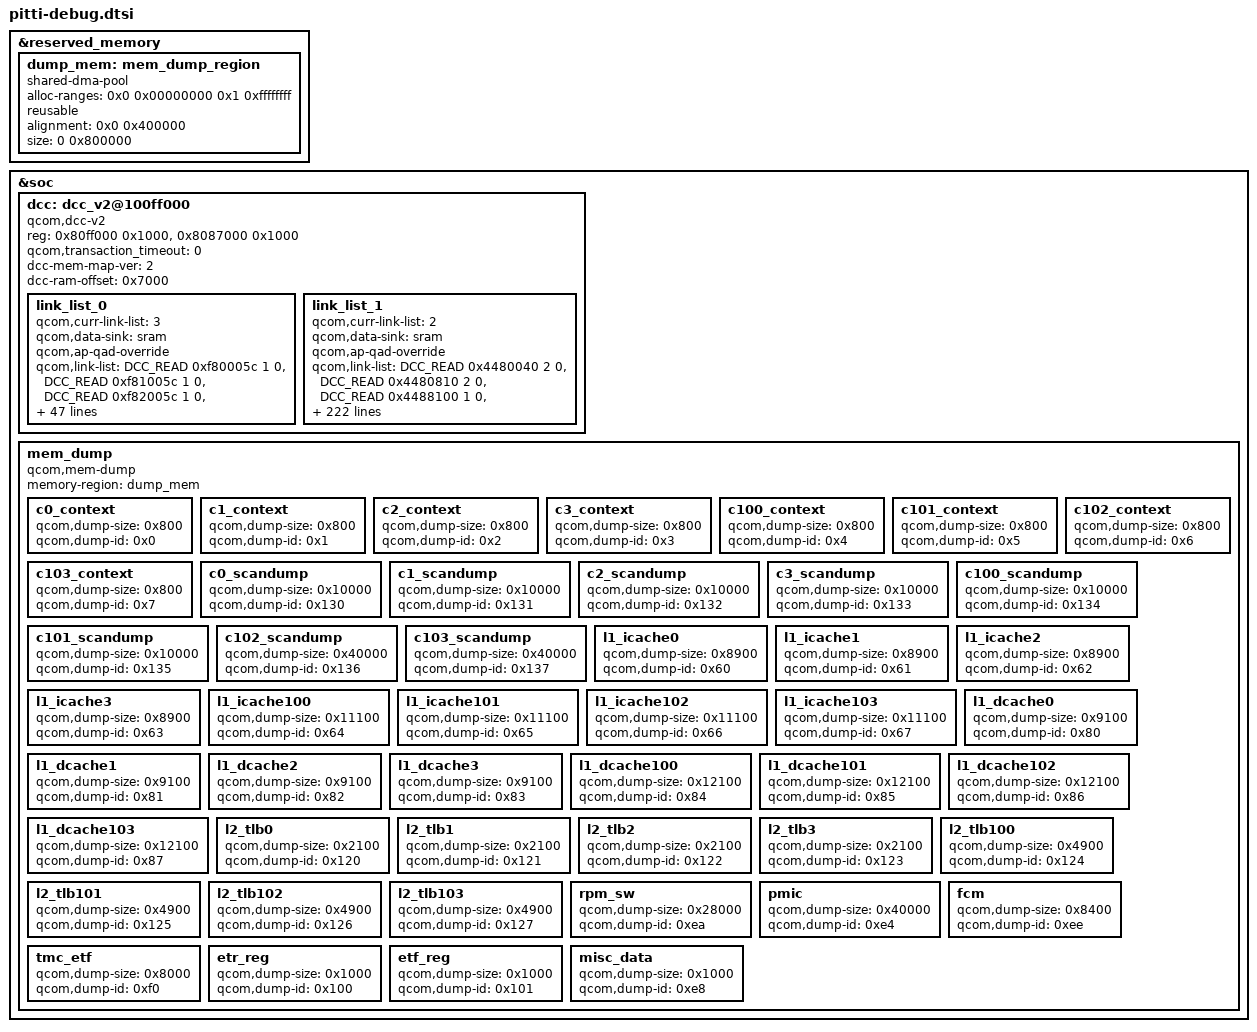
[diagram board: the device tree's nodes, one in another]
#include <dt-bindings/soc/qcom,dcc_v2.h>

&reserved_memory {
	#address-cells = <2>;
	#size-cells = <2>;
	ranges;

	dump_mem: mem_dump_region {
		compatible = "shared-dma-pool";
		alloc-ranges = <0x0 0x00000000 0x1 0xffffffff>;
		reusable;
		alignment = <0x0 0x400000>;
		size = <0 0x800000>;
	};
};

&soc {
	dcc: dcc_v2@100ff000 {
		compatible = "qcom,dcc-v2";
		reg = <0x80ff000 0x1000>,
		      <0x8087000 0x1000>;

		qcom,transaction_timeout = <0>;
		dcc-mem-map-ver = <2>;

		reg-names = "dcc-base", "dcc-ram-base";
		dcc-ram-offset = <0x7000>;

		link_list_0 {
			qcom,curr-link-list = <3>;
			qcom,data-sink = "sram";
			qcom,ap-qad-override;
			qcom,link-list = <DCC_READ 0xf80005c 1 0>,
				<DCC_READ 0xf81005c 1 0>,
				<DCC_READ 0xf82005c 1 0>,
				<DCC_READ 0xf83005c 1 0>,
				<DCC_READ 0xf84005c 1 0>,
				<DCC_READ 0xf85005c 1 0>,
				<DCC_READ 0xf86005c 1 0>,
				<DCC_READ 0xf87005c 1 0>,
				<DCC_READ 0xf40003c 1 0>,
				<DCC_READ 0x1b60100 11 0>,
				<DCC_READ 0x1880240 1 0>,
				<DCC_READ 0x1880248 1 0>,
				<DCC_READ 0x1880300 8 0>,
				<DCC_READ 0x1881100 2 0>,
				<DCC_READ 0x1900240 5 0>,
				<DCC_READ 0x1900258 1 0>,
				<DCC_READ 0x1900000 1 0>,
				<DCC_READ 0x1900010 1 0>,
				<DCC_READ 0x1900020 8 0>,
				<DCC_READ 0x1480140 1 0>,
				<DCC_READ 0x1481140 1 0>,
				<DCC_READ 0xf400038 1 0>,
				<DCC_READ 0xf41000c 1 0>,
				<DCC_READ 0xf400438 1 0>,
				<DCC_READ 0xf800058 1 0>,
				<DCC_READ 0xf810058 1 0>,
				<DCC_READ 0xf820058 1 0>,
				<DCC_READ 0xf830058 1 0>,
				<DCC_READ 0xf840058 1 0>,
				<DCC_READ 0xf850058 1 0>,
				<DCC_READ 0xf860058 1 0>,
				<DCC_READ 0xf870058 1 0>,
				<DCC_READ 0xf800060 1 0>,
				<DCC_READ 0xf810060 1 0>,
				<DCC_READ 0xf820060 1 0>,
				<DCC_READ 0xf830060 1 0>,
				<DCC_READ 0xf840060 1 0>,
				<DCC_READ 0xf850060 1 0>,
				<DCC_READ 0xf860060 1 0>,
				<DCC_READ 0xf870060 1 0>,
				<DCC_READ 0xf880060 1 0>,
				<DCC_READ 0xf600440 1 0>,
				<DCC_READ 0xf60043c 1 0>,
				<DCC_READ 0xf600404 1 0>,
				<DCC_READ 0x4407000 5 0>,
				<DCC_READ 0x4402000 2 0>,
				<DCC_READ 0xf200104 29 0>,
				<DCC_READ 0xf200184 29 0>,
				<DCC_READ 0xf200204 29 0>,
				<DCC_READ 0xf200284 29 0>;
		};

		link_list_1 {
			qcom,curr-link-list = <2>;
			qcom,data-sink = "sram";
			qcom,ap-qad-override;
			qcom,link-list = <DCC_READ 0x4480040 2 0>,
				<DCC_READ 0x4480810 2 0>,
				<DCC_READ 0x4488100 1 0>,
				<DCC_READ 0x4488400 2 0>,
				<DCC_READ 0x4488410 1 0>,
				<DCC_READ 0x4488420 2 0>,
				<DCC_READ 0x4488430 2 0>,
				<DCC_READ 0x4488440 2 0>,
				<DCC_READ 0x4488450 1 0>,
				<DCC_READ 0x448c100 1 0>,
				<DCC_READ 0x448c400 2 0>,
				<DCC_READ 0x448c410 1 0>,
				<DCC_READ 0x448c420 2 0>,
				<DCC_READ 0x448c430 2 0>,
				<DCC_READ 0x448c440 2 0>,
				<DCC_READ 0x448c450 1 0>,
				<DCC_READ 0x4490100 1 0>,
				<DCC_READ 0x4490400 2 0>,
				<DCC_READ 0x4490410 1 0>,
				<DCC_READ 0x4490420 2 0>,
				<DCC_READ 0x4490430 2 0>,
				<DCC_READ 0x4490440 2 0>,
				<DCC_READ 0x4490450 1 0>,
				<DCC_READ 0x4494100 1 0>,
				<DCC_READ 0x4494400 2 0>,
				<DCC_READ 0x4494410 1 0>,
				<DCC_READ 0x4494420 2 0>,
				<DCC_READ 0x4494430 2 0>,
				<DCC_READ 0x4494440 2 0>,
				<DCC_READ 0x4494450 1 0>,
				<DCC_READ 0x4498100 1 0>,
				<DCC_READ 0x4498400 2 0>,
				<DCC_READ 0x4498410 1 0>,
				<DCC_READ 0x4498420 2 0>,
				<DCC_READ 0x4498430 2 0>,
				<DCC_READ 0x4498440 2 0>,
				<DCC_READ 0x4498450 1 0>,
				<DCC_READ 0x449c400 2 0>,
				<DCC_READ 0x449c420 2 0>,
				<DCC_READ 0x449c430 1 0>,
				<DCC_READ 0x449c440 2 0>,
				<DCC_READ 0x449c450 1 0>,
				<DCC_READ 0x44a0400 2 0>,
				<DCC_READ 0x44a0420 2 0>,
				<DCC_READ 0x44a0430 1 0>,
				<DCC_READ 0x44a0440 2 0>,
				<DCC_READ 0x44a0450 1 0>,
				<DCC_READ 0x44a4100 1 0>,
				<DCC_READ 0x44a4400 2 0>,
				<DCC_READ 0x44a4410 1 0>,
				<DCC_READ 0x44a4420 2 0>,
				<DCC_READ 0x44a4430 2 0>,
				<DCC_READ 0x44a4440 2 0>,
				<DCC_READ 0x44a4450 1 0>,
				<DCC_READ 0x44b0020 1 0>,
				<DCC_READ 0x44b0100 1 0>,
				<DCC_READ 0x44b0120 5 0>,
				<DCC_READ 0x44b0140 1 0>,
				<DCC_READ 0x44b0450 1 0>,
				<DCC_READ 0x44b0500 1 0>,
				<DCC_READ 0x44b0520 1 0>,
				<DCC_READ 0x44b0560 1 0>,
				<DCC_READ 0x44b05a0 1 0>,
				<DCC_READ 0x44b0710 1 0>,
				<DCC_READ 0x44b0720 1 0>,
				<DCC_READ 0x44b0a40 1 0>,
				<DCC_READ 0x44b1800 1 0>,
				<DCC_READ 0x44b408c 1 0>,
				<DCC_READ 0x44b409c 3 0>,
				<DCC_READ 0x44b40b8 1 0>,
				<DCC_READ 0x44b5070 2 0>,
				<DCC_READ 0x44bc020 1 0>,
				<DCC_READ 0x44bc100 1 0>,
				<DCC_READ 0x44bc120 4 0>,
				<DCC_READ 0x44bc140 1 0>,
				<DCC_READ 0x44bc450 1 0>,
				<DCC_READ 0x44bc500 1 0>,
				<DCC_READ 0x44bc520 1 0>,
				<DCC_READ 0x44bc560 1 0>,
				<DCC_READ 0x44bc5a0 1 0>,
				<DCC_READ 0x44bc710 1 0>,
				<DCC_READ 0x44bc720 1 0>,
				<DCC_READ 0x44bca40 1 0>,
				<DCC_READ 0x44bd800 1 0>,
				<DCC_READ 0x44c008c 1 0>,
				<DCC_READ 0x44c009c 3 0>,
				<DCC_READ 0x44c00b8 1 0>,
				<DCC_READ 0x44c1070 2 0>,
				<DCC_READ 0x44c8220 1 0>,
				<DCC_READ 0x44c8400 7 0>,
				<DCC_READ 0x44c8420 9 0>,
				<DCC_READ 0x44c9800 1 0>,
				<DCC_READ 0x44d0000 1 0>,
				<DCC_READ 0x44d0020 1 0>,
				<DCC_READ 0x44d0030 1 0>,
				<DCC_READ 0x44d0100 1 0>,
				<DCC_READ 0x44d0108 2 0>,
				<DCC_READ 0x44d0400 1 0>,
				<DCC_READ 0x44d0410 1 0>,
				<DCC_READ 0x44d0420 1 0>,
				<DCC_READ 0x44d1800 1 0>,
				<DCC_READ 0x450002c 2 0>,
				<DCC_READ 0x4500094 1 0>,
				<DCC_READ 0x450009c 1 0>,
				<DCC_READ 0x45000c4 2 0>,
				<DCC_READ 0x45003dc 1 0>,
				<DCC_READ 0x45005d8 1 0>,
				<DCC_READ 0x450202c 2 0>,
				<DCC_READ 0x4502094 1 0>,
				<DCC_READ 0x450209c 1 0>,
				<DCC_READ 0x45020c4 2 0>,
				<DCC_READ 0x45023dc 1 0>,
				<DCC_READ 0x45025d8 1 0>,
				<DCC_READ 0x450302c 2 0>,
				<DCC_READ 0x4503094 1 0>,
				<DCC_READ 0x450309c 1 0>,
				<DCC_READ 0x45030c4 2 0>,
				<DCC_READ 0x45033dc 1 0>,
				<DCC_READ 0x45035d8 1 0>,
				<DCC_READ 0x4506028 2 0>,
				<DCC_READ 0x4506044 1 0>,
				<DCC_READ 0x4506094 1 0>,
				<DCC_READ 0x45061dc 1 0>,
				<DCC_READ 0x45061ec 1 0>,
				<DCC_READ 0x4506608 1 0>,
				<DCC_READ 0x450702c 2 0>,
				<DCC_READ 0x4507094 1 0>,
				<DCC_READ 0x450709c 1 0>,
				<DCC_READ 0x45070c4 2 0>,
				<DCC_READ 0x45073dc 1 0>,
				<DCC_READ 0x45075d8 1 0>,
				<DCC_READ 0x450902c 2 0>,
				<DCC_READ 0x4509094 1 0>,
				<DCC_READ 0x450909c 1 0>,
				<DCC_READ 0x45090c4 2 0>,
				<DCC_READ 0x45093dc 1 0>,
				<DCC_READ 0x45095d8 1 0>,
				<DCC_READ 0x450a02c 2 0>,
				<DCC_READ 0x450a094 3 0>,
				<DCC_READ 0x450a0c4 2 0>,
				<DCC_READ 0x450a3dc 1 0>,
				<DCC_READ 0x450a5d8 1 0>,
				<DCC_READ 0x4480000 1 0>,
				<DCC_READ 0x4488000 1 0>,
				<DCC_READ 0x44a0000 1 0>,
				<DCC_READ 0x448c000 1 0>,
				<DCC_READ 0x449c000 1 0>,
				<DCC_READ 0x4494000 1 0>,
				<DCC_READ 0x4490000 1 0>,
				<DCC_READ 0x44a4000 1 0>,
				<DCC_READ 0x4498000 1 0>,
				<DCC_READ 0x44b1000 1 0>,
				<DCC_READ 0x44b4000 1 0>,
				<DCC_READ 0x44b0000 1 0>,
				<DCC_READ 0x44b5000 1 0>,
				<DCC_READ 0x44bd000 1 0>,
				<DCC_READ 0x44c0000 1 0>,
				<DCC_READ 0x44bc000 1 0>,
				<DCC_READ 0x44c1000 1 0>,
				<DCC_READ 0x44d1000 1 0>,
				<DCC_READ 0x44c9000 1 0>,
				<DCC_READ 0x44c8000 1 0>,
				<DCC_READ 0x4414000 1 0>,
				<DCC_READ 0x4500000 1 0>,
				<DCC_READ 0x4506000 1 0>,
				<DCC_READ 0x4502000 1 0>,
				<DCC_READ 0x4503000 1 0>,
				<DCC_READ 0x4507000 1 0>,
				<DCC_READ 0x4509000 1 0>,
				<DCC_READ 0x450a000 1 0>,
				<DCC_READ 0x447d000 1 0>,
				<DCC_READ 0x447d100 1 0>,
				<DCC_READ 0x447d200 1 0>,
				<DCC_READ 0x0447d000 1 0>,
				<DCC_READ 0x0447d100 1 0>,
				<DCC_READ 0x0447d200 1 0>,
				<DCC_READ 0x04481000 1 0>,
				<DCC_READ 0x04482000 1 0>,
				<DCC_READ 0x04483000 1 0>,
				<DCC_READ 0x04484000 1 0>,
				<DCC_READ 0x04486000 1 0>,
				<DCC_READ 0x04488000 1 0>,
				<DCC_READ 0x04489000 1 0>,
				<DCC_READ 0x0448c000 1 0>,
				<DCC_READ 0x0448d000 1 0>,
				<DCC_READ 0x04490000 1 0>,
				<DCC_READ 0x04491000 1 0>,
				<DCC_READ 0x04494000 1 0>,
				<DCC_READ 0x04495000 1 0>,
				<DCC_READ 0x04498000 1 0>,
				<DCC_READ 0x04499000 1 0>,
				<DCC_READ 0x0449c000 1 0>,
				<DCC_READ 0x0449d000 1 0>,
				<DCC_READ 0x044a0000 1 0>,
				<DCC_READ 0x044a1000 1 0>,
				<DCC_READ 0x044a4000 1 0>,
				<DCC_READ 0x044a5000 1 0>,
				<DCC_READ 0x044b0000 1 0>,
				<DCC_READ 0x044b1000 1 0>,
				<DCC_READ 0x044b2000 1 0>,
				<DCC_READ 0x044b4000 1 0>,
				<DCC_READ 0x044b5000 1 0>,
				<DCC_READ 0x044b6000 1 0>,
				<DCC_READ 0x044b7000 1 0>,
				<DCC_READ 0x044bc000 1 0>,
				<DCC_READ 0x044bd000 1 0>,
				<DCC_READ 0x044be000 1 0>,
				<DCC_READ 0x044c0000 1 0>,
				<DCC_READ 0x044c1000 1 0>,
				<DCC_READ 0x044c2000 1 0>,
				<DCC_READ 0x044c3000 1 0>,
				<DCC_READ 0x044c8000 1 0>,
				<DCC_READ 0x044c9000 1 0>,
				<DCC_READ 0x044d0000 1 0>,
				<DCC_READ 0x044d1000 1 0>,
				<DCC_READ 0x04500000 1 0>,
				<DCC_READ 0x04502000 1 0>,
				<DCC_READ 0x04503000 1 0>,
				<DCC_READ 0x04506000 1 0>,
				<DCC_READ 0x04507000 1 0>,
				<DCC_READ 0x04509000 1 0>,
				<DCC_READ 0x0450a000 1 0>,
				<DCC_READ 0x0450e000 1 0>,
				<DCC_READ 0x0451e000 1 0>,
				<DCC_READ 0x0451f000 1 0>;
		};

	};

	mem_dump {
		compatible = "qcom,mem-dump";
		memory-region = <&dump_mem>;

		c0_context {
			qcom,dump-size = <0x800>;
			qcom,dump-id = <0x0>;
		};

		c1_context {
			qcom,dump-size = <0x800>;
			qcom,dump-id = <0x1>;
		};

		c2_context {
			qcom,dump-size = <0x800>;
			qcom,dump-id = <0x2>;
		};

		c3_context {
			qcom,dump-size = <0x800>;
			qcom,dump-id = <0x3>;
		};

		c100_context {
			qcom,dump-size = <0x800>;
			qcom,dump-id = <0x4>;
		};

		c101_context {
			qcom,dump-size = <0x800>;
			qcom,dump-id = <0x5>;
		};

		c102_context {
			qcom,dump-size = <0x800>;
			qcom,dump-id = <0x6>;
		};

		c103_context {
			qcom,dump-size = <0x800>;
			qcom,dump-id = <0x7>;
		};

		c0_scandump {
			qcom,dump-size = <0x10000>;
			qcom,dump-id = <0x130>;
		};

		c1_scandump {
			qcom,dump-size = <0x10000>;
			qcom,dump-id = <0x131>;
		};

		c2_scandump {
			qcom,dump-size = <0x10000>;
			qcom,dump-id = <0x132>;
		};

		c3_scandump {
			qcom,dump-size = <0x10000>;
			qcom,dump-id = <0x133>;
		};

		c100_scandump {
			qcom,dump-size = <0x10000>;
			qcom,dump-id = <0x134>;
		};

		c101_scandump {
			qcom,dump-size = <0x10000>;
			qcom,dump-id = <0x135>;
		};

		c102_scandump {
			qcom,dump-size = <0x40000>;
			qcom,dump-id = <0x136>;
		};

		c103_scandump {
			qcom,dump-size = <0x40000>;
			qcom,dump-id = <0x137>;
		};


		l1_icache0 {
			qcom,dump-size = <0x8900>;
			qcom,dump-id = <0x60>;
		};

		l1_icache1 {
			qcom,dump-size = <0x8900>;
			qcom,dump-id = <0x61>;
		};

		l1_icache2 {
			qcom,dump-size = <0x8900>;
			qcom,dump-id = <0x62>;
		};

		l1_icache3 {
			qcom,dump-size = <0x8900>;
			qcom,dump-id = <0x63>;
		};

		l1_icache100 {
			qcom,dump-size = <0x11100>;
			qcom,dump-id = <0x64>;
		};

		l1_icache101 {
			qcom,dump-size = <0x11100>;
			qcom,dump-id = <0x65>;
		};

		l1_icache102 {
			qcom,dump-size = <0x11100>;
			qcom,dump-id = <0x66>;
		};

		l1_icache103 {
			qcom,dump-size = <0x11100>;
			qcom,dump-id = <0x67>;
		};

		l1_dcache0 {
			qcom,dump-size = <0x9100>;
			qcom,dump-id = <0x80>;
		};

		l1_dcache1 {
			qcom,dump-size = <0x9100>;
			qcom,dump-id = <0x81>;
		};

		l1_dcache2 {
			qcom,dump-size = <0x9100>;
			qcom,dump-id = <0x82>;
		};

		l1_dcache3 {
			qcom,dump-size = <0x9100>;
			qcom,dump-id = <0x83>;
		};

		l1_dcache100 {
			qcom,dump-size = <0x12100>;
			qcom,dump-id = <0x84>;
		};

		l1_dcache101 {
			qcom,dump-size = <0x12100>;
			qcom,dump-id = <0x85>;
		};

		l1_dcache102 {
			qcom,dump-size = <0x12100>;
			qcom,dump-id = <0x86>;
		};

		l1_dcache103 {
			qcom,dump-size = <0x12100>;
			qcom,dump-id = <0x87>;
		};

		l2_tlb0 {
			qcom,dump-size = <0x2100>;
			qcom,dump-id = <0x120>;
		};

		l2_tlb1 {
			qcom,dump-size = <0x2100>;
			qcom,dump-id = <0x121>;
		};

		l2_tlb2 {
			qcom,dump-size = <0x2100>;
			qcom,dump-id = <0x122>;
		};

		l2_tlb3 {
			qcom,dump-size = <0x2100>;
			qcom,dump-id = <0x123>;
		};

		l2_tlb100 {
			qcom,dump-size = <0x4900>;
			qcom,dump-id = <0x124>;
		};

		l2_tlb101 {
			qcom,dump-size = <0x4900>;
			qcom,dump-id = <0x125>;
		};

		l2_tlb102 {
			qcom,dump-size = <0x4900>;
			qcom,dump-id = <0x126>;
		};

		l2_tlb103 {
			qcom,dump-size = <0x4900>;
			qcom,dump-id = <0x127>;
		};

		rpm_sw {
			qcom,dump-size = <0x28000>;
			qcom,dump-id = <0xea>;
		};

		pmic {
			qcom,dump-size = <0x40000>;
			qcom,dump-id = <0xe4>;
		};

		fcm {
			qcom,dump-size = <0x8400>;
			qcom,dump-id = <0xee>;
		};

		tmc_etf {
			qcom,dump-size = <0x8000>;
			qcom,dump-id = <0xf0>;
		};

		etr_reg {
			qcom,dump-size = <0x1000>;
			qcom,dump-id = <0x100>;
		};

		etf_reg {
			qcom,dump-size = <0x1000>;
			qcom,dump-id = <0x101>;
		};

		misc_data {
			qcom,dump-size = <0x1000>;
			qcom,dump-id = <0xe8>;
		};
	};
};
